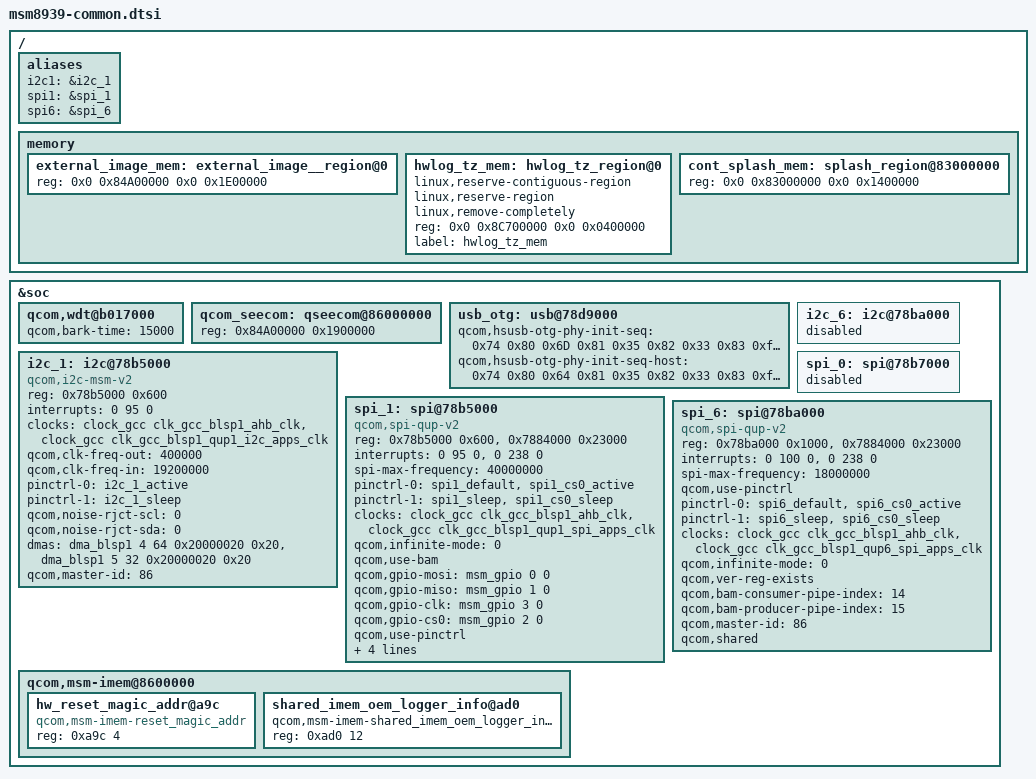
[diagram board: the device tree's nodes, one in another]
/* Copyright (c) 2014-2015, The Linux Foundation. All rights reserved.
 *
 * This program is free software; you can redistribute it and/or modify
 * it under the terms of the GNU General Public License version 2 and
 * only version 2 as published by the Free Software Foundation.
 *
 * This program is distributed in the hope that it will be useful,
 * but WITHOUT ANY WARRANTY; without even the implied warranty of
 * MERCHANTABILITY or FITNESS FOR A PARTICULAR PURPOSE.  See the
 * GNU General Public License for more details.
 */

/ {
	aliases {
		i2c1 = &i2c_1;
		spi1 = &spi_1;
		spi6 = &spi_6;
	};

	memory {
		external_image_mem: external_image__region@0 {
			reg = <0x0 0x84A00000 0x0 0x1E00000>;
		};

		hwlog_tz_mem: hwlog_tz_region@0 {
			linux,reserve-contiguous-region;
			linux,reserve-region;
			linux,remove-completely;
			reg = <0x0 0x8C700000 0x0 0x0400000>;
			label = "hwlog_tz_mem";
		};

		cont_splash_mem: splash_region@83000000 {
			reg = <0x0 0x83000000 0x0 0x1400000>;
		};
	};
};

&soc {
	qcom,wdt@b017000 {
		qcom,bark-time = <15000>;
	};

	qcom_seecom: qseecom@86000000 {
		reg = <0x84A00000 0x1900000>;
	};

	usb_otg: usb@78d9000 {
		qcom,hsusb-otg-phy-init-seq =
			<0x74 0x80 0x6D 0x81 0x35 0x82 0x33 0x83 0xffffffff>;
		qcom,hsusb-otg-phy-init-seq-host =
			<0x74 0x80 0x64 0x81 0x35 0x82 0x33 0x83 0xffffffff>;
		/delete-property/ qcom,hsusb-otg-disable-reset;
	};

	/delete-node/ dma_blsp1;

	i2c_1: i2c@78b5000 { /* BLSP1 QUP6 */
		compatible = "qcom,i2c-msm-v2";
		#address-cells = <1>;
		#size-cells = <0>;
		reg-names = "qup_phys_addr";
		reg = <0x78b5000 0x600>;
		interrupt-names = "qup_irq";
		interrupts = <0 95 0>;
		clocks = <&clock_gcc clk_gcc_blsp1_ahb_clk>,
			 <&clock_gcc clk_gcc_blsp1_qup1_i2c_apps_clk>;
		clock-names = "iface_clk", "core_clk";
		qcom,clk-freq-out = <400000>;
		qcom,clk-freq-in  = <19200000>;
		pinctrl-names = "i2c_active", "i2c_sleep";
		pinctrl-0 = <&i2c_1_active>;
		pinctrl-1 = <&i2c_1_sleep>;
		qcom,noise-rjct-scl = <0>;
		qcom,noise-rjct-sda = <0>;
		dmas = <&dma_blsp1 4 64 0x20000020 0x20>,
			<&dma_blsp1 5 32 0x20000020 0x20>;
		dma-names = "tx", "rx";
		qcom,master-id = <86>;
	};

	i2c_6: i2c@78ba000 { /* BLSP1 QUP6 */
		status = "disabled";
	};

	spi_0: spi@78b7000 { /* BLSP1 QUP3 */
		status = "disabled";
	};

	spi_1: spi@78b5000 { /* BLSP1 QUP1 */
		compatible = "qcom,spi-qup-v2";
		#address-cells = <1>;
		#size-cells = <0>;
		reg-names = "spi_physical", "spi_bam_physical";
		reg = <0x78b5000 0x600>,
			<0x7884000 0x23000>;
		interrupt-names = "spi_irq", "spi_bam_irq";
		interrupts = <0 95 0>, <0 238 0>;
		spi-max-frequency = <40000000>;
		pinctrl-names = "spi_default", "spi_sleep";
		pinctrl-0 = <&spi1_default &spi1_cs0_active>;
		pinctrl-1 = <&spi1_sleep &spi1_cs0_sleep>;
		clocks = <&clock_gcc clk_gcc_blsp1_ahb_clk>,
			<&clock_gcc clk_gcc_blsp1_qup1_spi_apps_clk>;
		clock-names = "iface_clk", "core_clk";
		qcom,infinite-mode = <0>;
		qcom,use-bam;
		qcom,gpio-mosi = <&msm_gpio 0 0>;
		qcom,gpio-miso = <&msm_gpio 1 0>;
		qcom,gpio-clk = <&msm_gpio 3 0>;
		qcom,gpio-cs0 = <&msm_gpio 2 0>;
		qcom,use-pinctrl;
		qcom,ver-reg-exists;
		qcom,bam-consumer-pipe-index = <4>;
		qcom,bam-producer-pipe-index = <5>;
		qcom,master-id = <86>;
	};

	spi_6: spi@78ba000 {  /* BLSP1 QUP6 */
		compatible = "qcom,spi-qup-v2";
		#address-cells = <1>;
		#size-cells = <0>;
		reg-names = "spi_physical", "spi_bam_physical";
		reg = <0x78ba000 0x1000>,
			<0x7884000 0x23000>;
		interrupt-names = "spi_irq", "spi_bam_irq";
		interrupts = <0 100 0>, <0 238 0>;
		spi-max-frequency = <18000000>;
		qcom,use-pinctrl;
		pinctrl-names = "spi_default", "spi_sleep";
		pinctrl-0 = <&spi6_default &spi6_cs0_active>;
		pinctrl-1 = <&spi6_sleep &spi6_cs0_sleep>;
		clocks = <&clock_gcc clk_gcc_blsp1_ahb_clk>,
			<&clock_gcc clk_gcc_blsp1_qup6_spi_apps_clk>;
		clock-names = "iface_clk", "core_clk";
		qcom,infinite-mode = <0>;
		qcom,ver-reg-exists;
		qcom,bam-consumer-pipe-index = <14>;
		qcom,bam-producer-pipe-index = <15>;
		qcom,master-id = <86>;
		qcom,shared;
	};

	qcom,msm-imem@8600000 {
		hw_reset_magic_addr@a9c {
			compatible = "qcom,msm-imem-reset_magic_addr";
			reg = <0xa9c 4>;
		};

		shared_imem_oem_logger_info@ad0 {
			compatible = "qcom,msm-imem-shared_imem_oem_logger_info";
			reg = <0xad0 12>;
		};
	};
};
